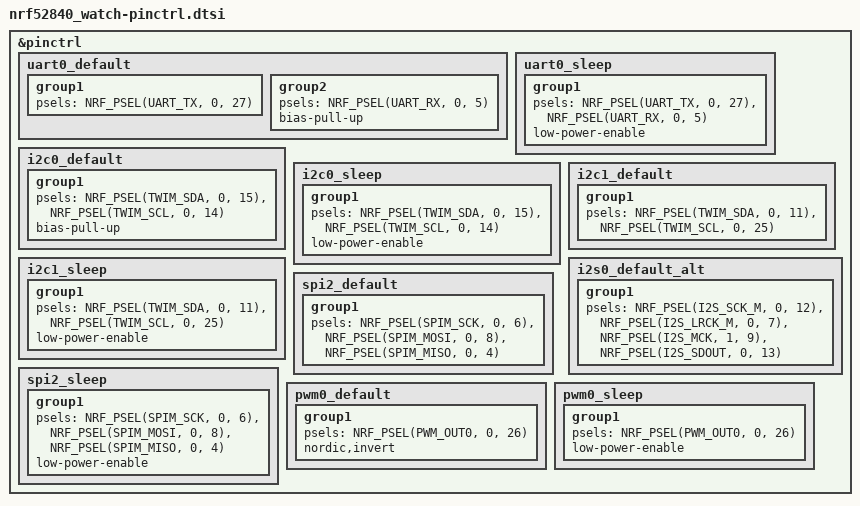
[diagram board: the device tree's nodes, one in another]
&pinctrl {
        uart0_default: uart0_default {
                group1 {
                        psels = <NRF_PSEL(UART_TX, 0, 27)>;
                };
                group2 {
                        psels = <NRF_PSEL(UART_RX, 0, 5)>;
                        bias-pull-up;
                };
        };

        uart0_sleep: uart0_sleep {
                group1 {
                        psels = <NRF_PSEL(UART_TX, 0, 27)>,
                                <NRF_PSEL(UART_RX, 0, 5)>;
                        low-power-enable;
                };
        };

        i2c0_default: i2c0_default {
                group1 {
                        psels = <NRF_PSEL(TWIM_SDA, 0, 15)>,
                                <NRF_PSEL(TWIM_SCL, 0, 14)>;
                        bias-pull-up;
                };
        };

        i2c0_sleep: i2c0_sleep {
                group1 {
                        psels = <NRF_PSEL(TWIM_SDA, 0, 15)>,
                                <NRF_PSEL(TWIM_SCL, 0, 14)>;
                        low-power-enable;
                };
        };

        i2c1_default: i2c1_default {
                group1 {
                        psels = <NRF_PSEL(TWIM_SDA, 0, 11)>,
                                <NRF_PSEL(TWIM_SCL, 0, 25)>;
                };
        };

        i2c1_sleep: i2c1_sleep {
                group1 {
                        psels = <NRF_PSEL(TWIM_SDA, 0, 11)>,
                                <NRF_PSEL(TWIM_SCL, 0, 25)>;
                        low-power-enable;
                };
        };

        i2s0_default_alt: i2s0_default_alt {
                group1 {
                        psels = <NRF_PSEL(I2S_SCK_M, 0, 12)>,
                                <NRF_PSEL(I2S_LRCK_M, 0, 7)>,
                                <NRF_PSEL(I2S_MCK, 1, 9)>,
                                <NRF_PSEL(I2S_SDOUT, 0, 13)>;
                };
        };

        spi2_default: spi2_default {
                group1 {
                        psels = <NRF_PSEL(SPIM_SCK, 0, 6)>,
                                <NRF_PSEL(SPIM_MOSI, 0, 8)>,
                                <NRF_PSEL(SPIM_MISO, 0, 4)>;
                };
        };

        spi2_sleep: spi2_sleep {
                group1 {
                        psels = <NRF_PSEL(SPIM_SCK, 0, 6)>,
                                <NRF_PSEL(SPIM_MOSI, 0, 8)>,
                                <NRF_PSEL(SPIM_MISO, 0, 4)>;
                        low-power-enable;
                };
        };

        pwm0_default: pwm0_default {
		group1 {
			psels = <NRF_PSEL(PWM_OUT0, 0, 26)>;
			nordic,invert;
		};
	};

	pwm0_sleep: pwm0_sleep {
		group1 {
			psels = <NRF_PSEL(PWM_OUT0, 0, 26)>;
			low-power-enable;
		};
	};
};
